# DSPIC33FJ128MC804 register map
Vendor: Microchip
Registers are 16-bit, read-write, reset 0x0 unless marked. A register's access mark holds for its fields unless they carry their own. Addresses are absolute, and some are shared; only a register's first bit layout is shown; [hi:lo] are bit positions; {n}, {i} and the like mark numbered series; 'fields as' and 'values as' point back to an identical list.

## SFR
{0x0+2i} WREG{i} (i=0..14)
0x1E WREG15 reset 0x800
0x20 SPLIM
0x22 ACCAL reset not defined — (power-on value xxxxxxxxxxxxxxxx)
0x24 ACCAH reset not defined — (power-on value xxxxxxxxxxxxxxxx)
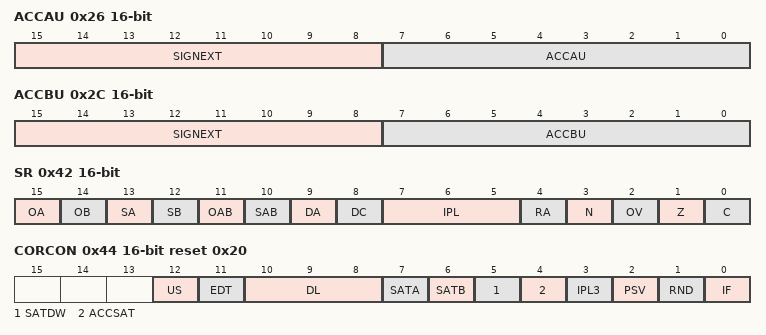
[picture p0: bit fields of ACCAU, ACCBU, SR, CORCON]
0x26 ACCAU reset not defined — (power-on value 00000000xxxxxxxx)
  [15:8] SIGNEXT ro, [7:0] ACCAU
0x28 ACCBL reset not defined — (power-on value xxxxxxxxxxxxxxxx)
0x2A ACCBH reset not defined — (power-on value xxxxxxxxxxxxxxxx)
0x2C ACCBU reset not defined — (power-on value 00000000xxxxxxxx)
  [15:8] SIGNEXT ro, [7:0] ACCBU
0x2E PCL ro
0x30 PCH ro
  [6:0] PCH
0x32 TBLPAG
  [7:0] TBLPAG
0x34 PSVPAG
  [7:0] PSVPAG
0x36 RCOUNT reset not defined — (power-on value --xxxxxxxxxxxxxx)
  [13:0] RCOUNT
0x38 DCOUNT reset not defined — (power-on value --xxxxxxxxxxxxxx)
  [13:0] DCOUNT
0x3A DOSTARTL reset not defined — (power-on value xxxxxxxxxxxxxxx0)
0x3C DOSTARTH reset not defined — (power-on value ----------xxxxxx)
  [5:0] DOSTARTH
0x3E DOENDL reset not defined — (power-on value xxxxxxxxxxxxxxx0)
0x40 DOENDH reset not defined — (power-on value ----------xxxxxx)
  [5:0] DOENDH
0x42 SR
  [15] OA ro
  [14] OB ro
  [13] SA — (can only be cleared)
  [12] SB — (can only be cleared)
  [11] OAB ro
  [10] SAB — (can only be cleared)
  [9] DA ro
  [8] DC
  [7:5] IPL
  [4] RA ro
  [3] N
  [2] OV
  [1] Z
  [0] C
0x44 CORCON reset 0x20
  [12] US
  [11] EDT wo
  [10:8] DL ro
  [7] SATA
  [6] SATB
  [5] SATDW
  [4] ACCSAT
  [3] IPL3 — (can only be cleared)
  [2] PSV
  [1] RND
  [0] IF
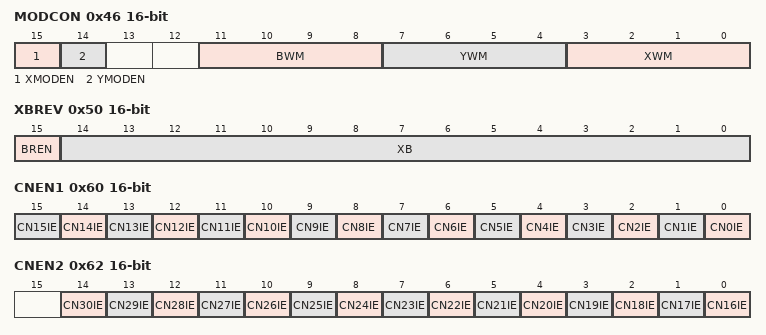
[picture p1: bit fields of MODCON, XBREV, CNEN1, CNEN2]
0x46 MODCON
  [15] XMODEN, [14] YMODEN, [11:8] BWM, [7:4] YWM, [3:0] XWM
0x48 XMODSRT reset not defined — (power-on value xxxxxxxxxxxxxxx0)
  [15:0] XS
0x4A XMODEND reset not defined — (power-on value xxxxxxxxxxxxxxx1)
  [15:0] XE
0x4C YMODSRT reset not defined — (power-on value xxxxxxxxxxxxxxx0)
  [15:0] YS
0x4E YMODEND reset not defined — (power-on value xxxxxxxxxxxxxxx1)
  [15:0] YE
0x50 XBREV reset not defined — (power-on value 0xxxxxxxxxxxxxxx)
  [15] BREN, [14:0] XB
0x52 DISICNT reset not defined — (power-on value --xxxxxxxxxxxxxx)
  [13:0] DISICNT
0x60 CNEN1
  [n] CN{n}IE (n=0..15)
0x62 CNEN2
  [n-16] CN{n}IE (n=16..30)
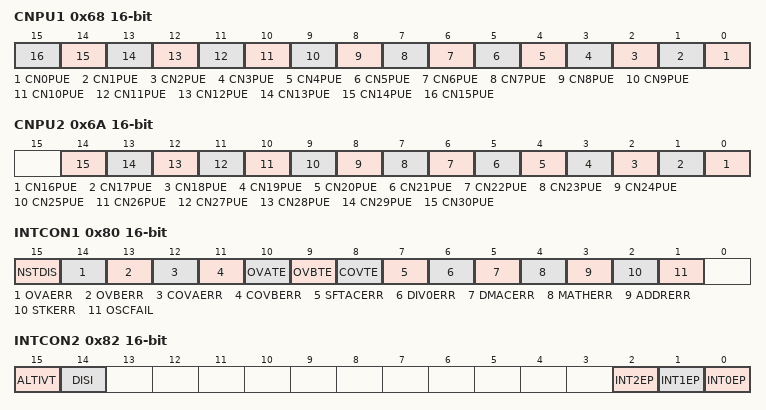
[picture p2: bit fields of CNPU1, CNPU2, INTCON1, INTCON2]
0x68 CNPU1
  [n] CN{n}PUE (n=0..15)
0x6A CNPU2
  [n-16] CN{n}PUE (n=16..30)
0x80 INTCON1
  [15] NSTDIS, [14] OVAERR ro, [13] OVBERR ro, [12] COVAERR ro, [11] COVBERR ro, [10] OVATE, [9] OVBTE, [8] COVTE, [7] SFTACERR ro, [6] DIV0ERR ro, [5] DMACERR, [4] MATHERR, [3] ADDRERR, [2] STKERR, [1] OSCFAIL
0x82 INTCON2
  [15] ALTIVT, [14] DISI ro, [2] INT2EP, [1] INT1EP, [0] INT0EP
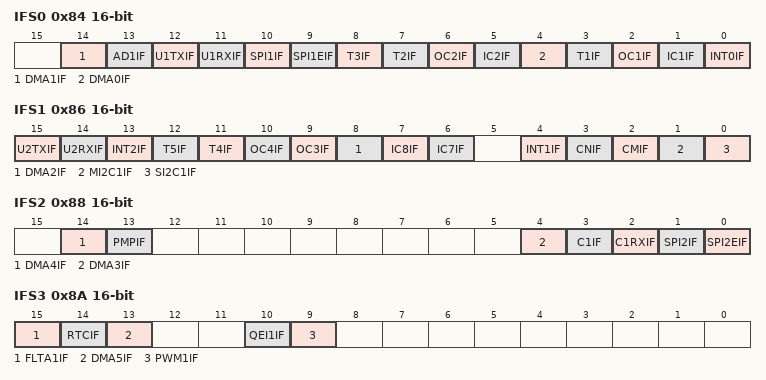
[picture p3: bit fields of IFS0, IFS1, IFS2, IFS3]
0x84 IFS0
  [14] DMA1IF, [13] AD1IF, [12] U1TXIF, [11] U1RXIF, [10] SPI1IF, [9] SPI1EIF, [8] T3IF, [7] T2IF, [6] OC2IF, [5] IC2IF, [4] DMA0IF, [3] T1IF, [2] OC1IF, [1] IC1IF, [0] INT0IF
0x86 IFS1
  [15] U2TXIF, [14] U2RXIF, [13] INT2IF, [12] T5IF, [11] T4IF, [10] OC4IF, [9] OC3IF, [8] DMA2IF, [7] IC8IF, [6] IC7IF, [4] INT1IF, [3] CNIF, [2] CMIF, [1] MI2C1IF, [0] SI2C1IF
0x88 IFS2
  [14] DMA4IF, [13] PMPIF, [4] DMA3IF, [3] C1IF, [2] C1RXIF, [1] SPI2IF, [0] SPI2EIF
0x8A IFS3
  [15] FLTA1IF, [14] RTCIF, [13] DMA5IF, [10] QEI1IF, [9] PWM1IF
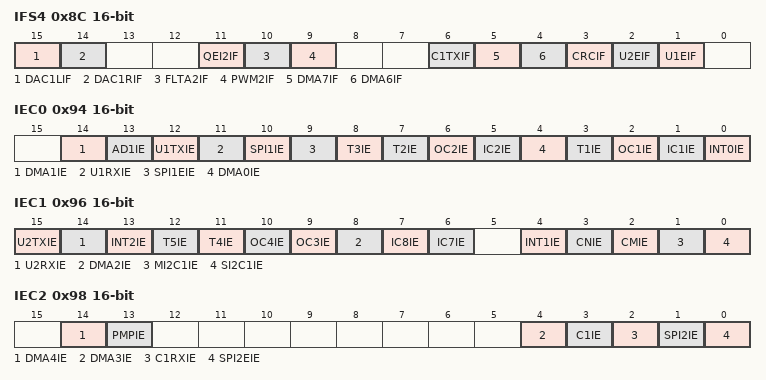
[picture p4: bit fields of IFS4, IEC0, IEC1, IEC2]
0x8C IFS4
  [15] DAC1LIF, [14] DAC1RIF, [11] QEI2IF, [10] FLTA2IF, [9] PWM2IF, [6] C1TXIF, [5] DMA7IF, [4] DMA6IF, [3] CRCIF, [2] U2EIF, [1] U1EIF
0x94 IEC0
  [14] DMA1IE, [13] AD1IE, [12] U1TXIE, [11] U1RXIE, [10] SPI1IE, [9] SPI1EIE, [8] T3IE, [7] T2IE, [6] OC2IE, [5] IC2IE, [4] DMA0IE, [3] T1IE, [2] OC1IE, [1] IC1IE, [0] INT0IE
0x96 IEC1
  [15] U2TXIE, [14] U2RXIE, [13] INT2IE, [12] T5IE, [11] T4IE, [10] OC4IE, [9] OC3IE, [8] DMA2IE, [7] IC8IE, [6] IC7IE, [4] INT1IE, [3] CNIE, [2] CMIE, [1] MI2C1IE, [0] SI2C1IE
0x98 IEC2
  [14] DMA4IE, [13] PMPIE, [4] DMA3IE, [3] C1IE, [2] C1RXIE, [1] SPI2IE, [0] SPI2EIE
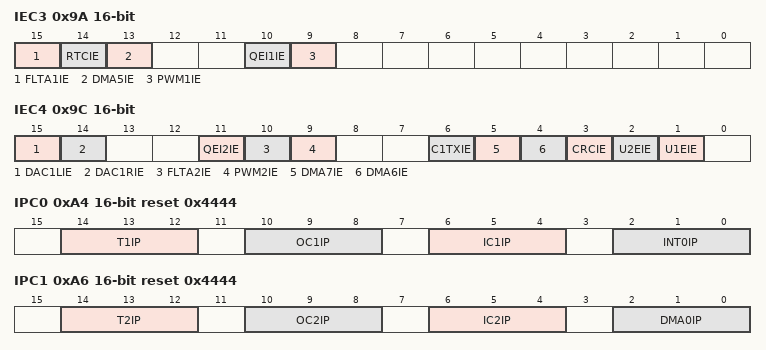
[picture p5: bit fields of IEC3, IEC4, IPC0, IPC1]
0x9A IEC3
  [15] FLTA1IE, [14] RTCIE, [13] DMA5IE, [10] QEI1IE, [9] PWM1IE
0x9C IEC4
  [15] DAC1LIE, [14] DAC1RIE, [11] QEI2IE, [10] FLTA2IE, [9] PWM2IE, [6] C1TXIE, [5] DMA7IE, [4] DMA6IE, [3] CRCIE, [2] U2EIE, [1] U1EIE
0xA4 IPC0 reset 0x4444
  [14:12] T1IP, [10:8] OC1IP, [6:4] IC1IP, [2:0] INT0IP
0xA6 IPC1 reset 0x4444
  [14:12] T2IP, [10:8] OC2IP, [6:4] IC2IP, [2:0] DMA0IP
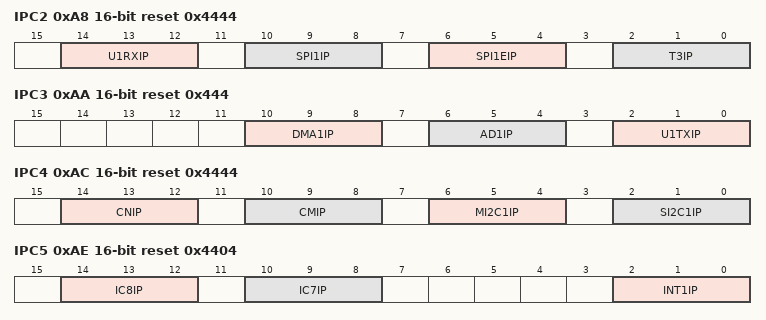
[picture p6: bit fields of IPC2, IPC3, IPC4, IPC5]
0xA8 IPC2 reset 0x4444
  [14:12] U1RXIP, [10:8] SPI1IP, [6:4] SPI1EIP, [2:0] T3IP
0xAA IPC3 reset 0x444
  [10:8] DMA1IP, [6:4] AD1IP, [2:0] U1TXIP
0xAC IPC4 reset 0x4444
  [14:12] CNIP, [10:8] CMIP, [6:4] MI2C1IP, [2:0] SI2C1IP
0xAE IPC5 reset 0x4404
  [14:12] IC8IP, [10:8] IC7IP, [2:0] INT1IP
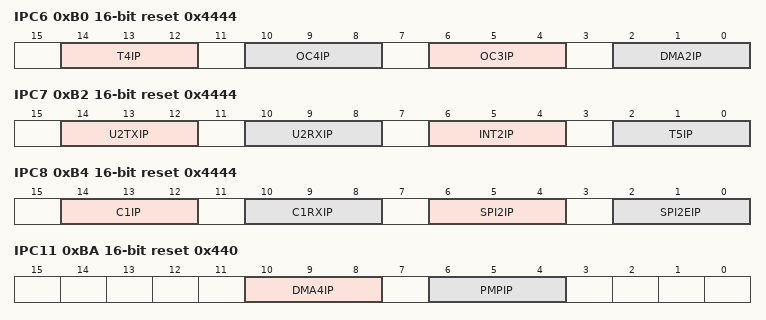
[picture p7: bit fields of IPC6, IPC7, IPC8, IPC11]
0xB0 IPC6 reset 0x4444
  [14:12] T4IP, [10:8] OC4IP, [6:4] OC3IP, [2:0] DMA2IP
0xB2 IPC7 reset 0x4444
  [14:12] U2TXIP, [10:8] U2RXIP, [6:4] INT2IP, [2:0] T5IP
0xB4 IPC8 reset 0x4444
  [14:12] C1IP, [10:8] C1RXIP, [6:4] SPI2IP, [2:0] SPI2EIP
0xB6 IPC9 reset 0x4
  [2:0] DMA3IP
0xBA IPC11 reset 0x440
  [10:8] DMA4IP, [6:4] PMPIP
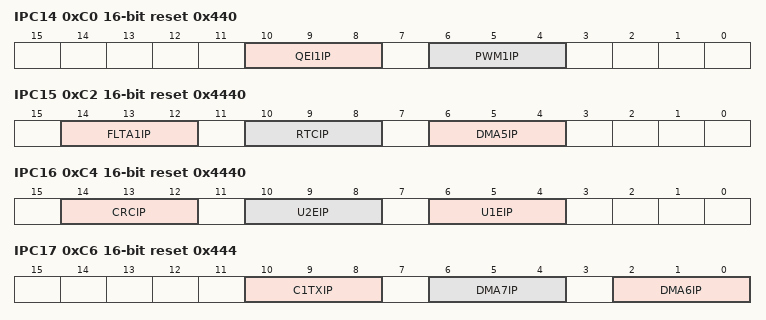
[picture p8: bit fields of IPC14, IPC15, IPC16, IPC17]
0xC0 IPC14 reset 0x440
  [10:8] QEI1IP, [6:4] PWM1IP
0xC2 IPC15 reset 0x4440
  [14:12] FLTA1IP, [10:8] RTCIP, [6:4] DMA5IP
0xC4 IPC16 reset 0x4440
  [14:12] CRCIP, [10:8] U2EIP, [6:4] U1EIP
0xC6 IPC17 reset 0x444
  [10:8] C1TXIP, [6:4] DMA7IP, [2:0] DMA6IP
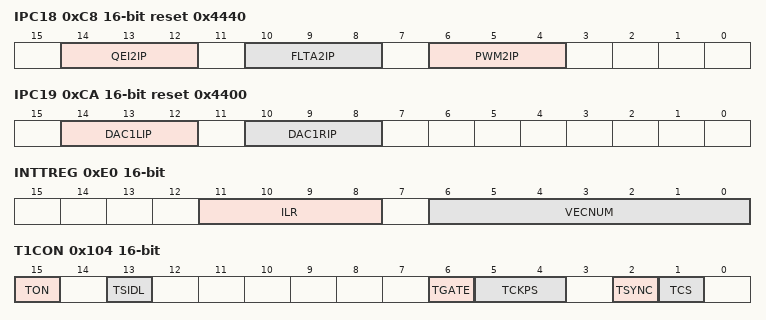
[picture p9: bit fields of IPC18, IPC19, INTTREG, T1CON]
0xC8 IPC18 reset 0x4440
  [14:12] QEI2IP, [10:8] FLTA2IP, [6:4] PWM2IP
0xCA IPC19 reset 0x4400
  [14:12] DAC1LIP, [10:8] DAC1RIP
0xE0 INTTREG ro
  [11:8] ILR, [6:0] VECNUM
0x100 TMR1 reset not defined — (power-on value xxxxxxxxxxxxxxxx)
0x102 PR1 reset 0xFFFF
0x104 T1CON
  [15] TON, [13] TSIDL, [6] TGATE, [5:4] TCKPS, [2] TSYNC, [1] TCS
0x106 TMR2 reset not defined — (power-on value xxxxxxxxxxxxxxxx)
0x108 TMR3HLD reset not defined — (power-on value xxxxxxxxxxxxxxxx)
0x10A TMR3 reset not defined — (power-on value xxxxxxxxxxxxxxxx)
0x10C PR2 reset 0xFFFF
0x10E PR3 reset 0xFFFF
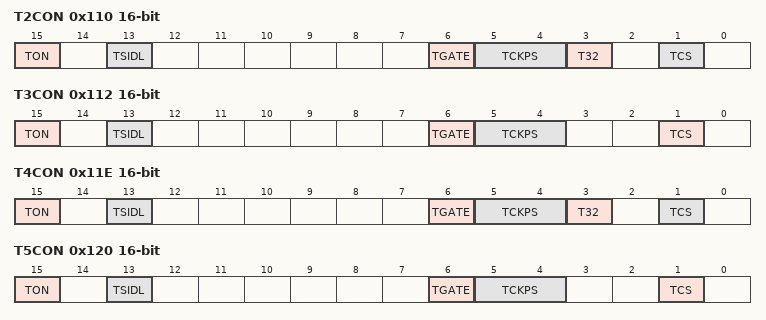
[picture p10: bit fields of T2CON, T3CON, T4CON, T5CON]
0x110 T2CON
  [15] TON, [13] TSIDL, [6] TGATE, [5:4] TCKPS, [3] T32, [1] TCS
0x112 T3CON
  [15] TON, [13] TSIDL, [6] TGATE, [5:4] TCKPS, [1] TCS
0x114 TMR4 reset not defined — (power-on value xxxxxxxxxxxxxxxx)
0x116 TMR5HLD reset not defined — (power-on value xxxxxxxxxxxxxxxx)
0x118 TMR5 reset not defined — (power-on value xxxxxxxxxxxxxxxx)
0x11A PR4 reset 0xFFFF
0x11C PR5 reset 0xFFFF
0x11E T4CON
  [15] TON, [13] TSIDL, [6] TGATE, [5:4] TCKPS, [3] T32, [1] TCS
0x120 T5CON
  [15] TON, [13] TSIDL, [6] TGATE, [5:4] TCKPS, [1] TCS
0x140 IC1BUF ro reset not defined — (power-on value xxxxxxxxxxxxxxxx)
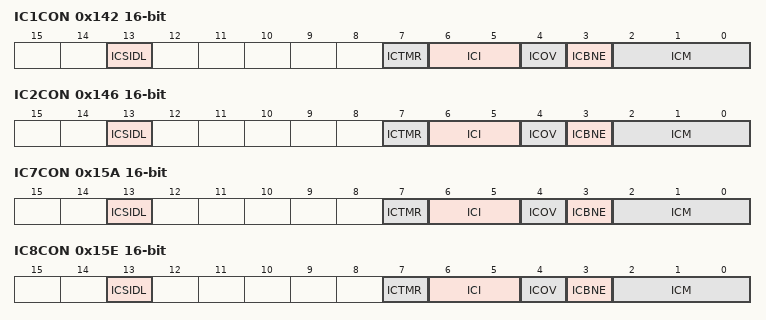
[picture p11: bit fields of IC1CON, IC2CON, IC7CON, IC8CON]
0x142 IC1CON
  [13] ICSIDL, [7] ICTMR, [6:5] ICI, [4] ICOV ro, [3] ICBNE ro, [2:0] ICM
0x144 IC2BUF ro reset not defined — (power-on value xxxxxxxxxxxxxxxx)
0x146 IC2CON
  fields as IC1CON
0x158 IC7BUF ro reset not defined — (power-on value xxxxxxxxxxxxxxxx)
0x15A IC7CON
  fields as IC1CON
0x15C IC8BUF ro reset not defined — (power-on value xxxxxxxxxxxxxxxx)
0x15E IC8CON
  fields as IC1CON
{0x17A+6i} OC{i}RS reset not defined (i=1..4) — (power-on value xxxxxxxxxxxxxxxx)
{0x17C+6i} OC{i}R reset not defined (i=1..4) — (power-on value xxxxxxxxxxxxxxxx)
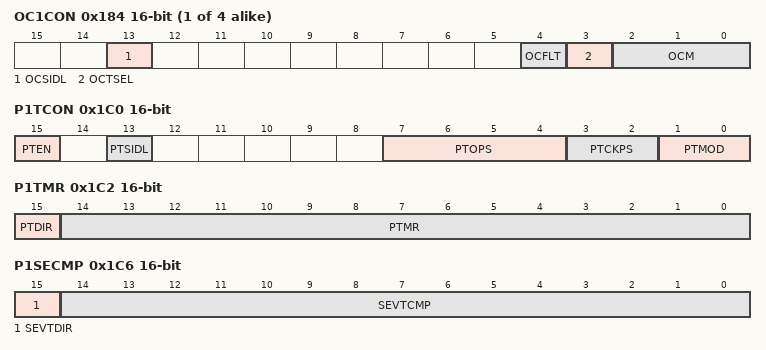
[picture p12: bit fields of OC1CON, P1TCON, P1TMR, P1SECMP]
{0x17E+6i} OC{i}CON (i=1..4)
  [13] OCSIDL, [4] OCFLT ro, [3] OCTSEL, [2:0] OCM
0x1C0 P1TCON
  [15] PTEN, [13] PTSIDL, [7:4] PTOPS, [3:2] PTCKPS, [1:0] PTMOD
0x1C2 P1TMR
  [15] PTDIR ro, [14:0] PTMR
0x1C4 P1TPER
  [14:0] PTPER
0x1C6 P1SECMP
  [15] SEVTDIR, [14:0] SEVTCMP
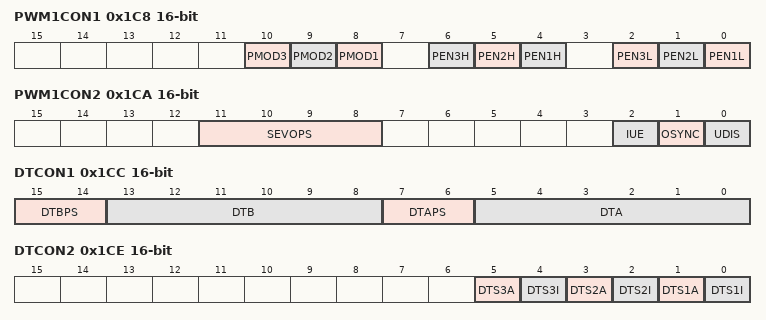
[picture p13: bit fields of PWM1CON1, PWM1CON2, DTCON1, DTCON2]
0x1C8 PWM1CON1
  [10] PMOD3, [9] PMOD2, [8] PMOD1, [6] PEN3H, [5] PEN2H, [4] PEN1H, [2] PEN3L, [1] PEN2L, [0] PEN1L
0x1CA PWM1CON2
  [11:8] SEVOPS, [2] IUE, [1] OSYNC, [0] UDIS
0x1CC DTCON1
  [15:14] DTBPS, [13:8] DTB, [7:6] DTAPS, [5:0] DTA
0x1CE DTCON2
  [5] DTS3A, [4] DTS3I, [3] DTS2A, [2] DTS2I, [1] DTS1A, [0] DTS1I
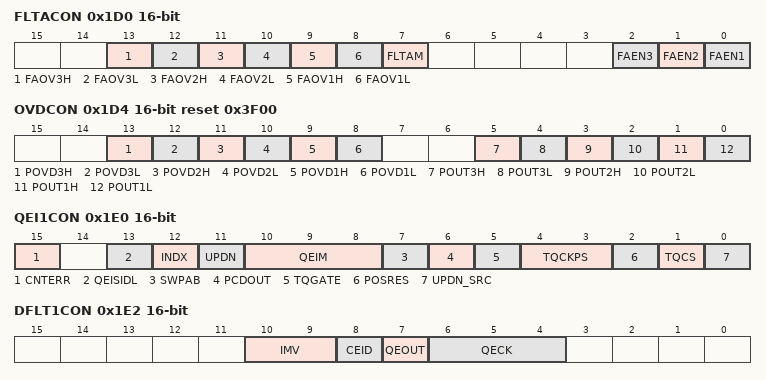
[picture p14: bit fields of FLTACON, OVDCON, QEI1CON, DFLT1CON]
0x1D0 FLTACON
  [13] FAOV3H, [12] FAOV3L, [11] FAOV2H, [10] FAOV2L, [9] FAOV1H, [8] FAOV1L, [7] FLTAM, [2] FAEN3, [1] FAEN2, [0] FAEN1
0x1D4 OVDCON reset 0x3F00
  [13] POVD3H, [12] POVD3L, [11] POVD2H, [10] POVD2L, [9] POVD1H, [8] POVD1L, [5] POUT3H, [4] POUT3L, [3] POUT2H, [2] POUT2L, [1] POUT1H, [0] POUT1L
{0x1D4+2i} P1DC{i} (i=1..3)
  [15:0] PDC{i}
0x1E0 QEI1CON
  [15] CNTERR, [13] QEISIDL, [12] INDX, [11] UPDN, [10:8] QEIM, [7] SWPAB, [6] PCDOUT, [5] TQGATE, [4:3] TQCKPS, [2] POSRES, [1] TQCS, [0] UPDN_SRC
0x1E2 DFLT1CON
  [10:9] IMV, [8] CEID, [7] QEOUT, [6:4] QECK
0x1E4 POS1CNT
0x1E6 MAX1CNT
0x1F0 QEI2CON
  fields as QEI1CON
0x1F2 DFLT2CON
  [10:9] IMV, [8] CEID, [7] QEOUT, [6:4] QECK
0x1F4 POS2CNT
0x1F6 MAX2CNT
0x200 I2C1RCV ro
  [7:0] I2C1RCV
0x202 I2C1TRN wo reset 0xFF
  [7:0] I2C1TRN
0x204 I2C1BRG
  [8:0] I2C1BRG
0x206 I2C1CON reset 0x1000
  [15] I2CEN, [13] I2CSIDL, [12] SCLREL, [11] IPMIEN, [10] A10M, [9] DISSLW, [8] SMEN, [7] GCEN, [6] STREN, [5] ACKDT, [4] ACKEN, [3] RCEN, [2] PEN, [1] RSEN, [0] SEN
0x208 I2C1STAT
  [15] ACKSTAT ro
  [14] TRSTAT ro
  [10] BCL ro
  [9] GCSTAT ro
  [8] ADD10 ro
  [7] IWCOL — (can only be cleared)
  [6] I2COV — (can only be cleared)
  [5] D_A ro
  [4] P — (can only be cleared)
  [3] S — (can only be cleared)
  [2] R_W ro
  [1] RBF ro
  [0] TBF ro
0x20A I2C1ADD
  [9:0] I2C1ADD
0x20C I2C1MSK
  [9:0] AMSK
0x220 U1MODE
  [15] UARTEN, [13] USIDL, [12] IREN, [11] RTSMD, [9:8] UEN, [7] WAKE, [6] LPBACK, [5] ABAUD, [4] URXINV, [3] BRGH, [2:1] PDSEL, [0] STSEL
0x222 U1STA reset 0x110
  [15] UTXISEL1
  [14] UTXINV
  [13] UTXISEL0
  [11] UTXBRK
  [10] UTXEN
  [9] UTXBF ro
  [8] TRMT ro
  [7:6] URXISEL
  [5] ADDEN
  [4] RIDLE ro
  [3] PERR ro
  [2] FERR ro
  [1] OERR — (can only be cleared)
  [0] URXDA ro
0x224 U1TXREG wo
  [n] UTXREG{n} (n=0..8)
0x226 U1RXREG ro
  [n] URXREG{n} (n=0..8)
0x228 U1BRG
  [15:0] BRG
0x230 U2MODE
  fields as U1MODE
0x232 U2STA reset 0x110
  fields as U1STA
0x234 U2TXREG wo
  [n] UTXREG{n} (n=0..8)
0x236 U2RXREG ro
  [n] URXREG{n} (n=0..8)
0x238 U2BRG
  [15:0] BRG
0x240 SPI1STAT
  [15] SPIEN
  [13] SPISIDL
  [6] SPIROV — (can only be cleared)
  [1] SPITBF
  [0] SPIRBF
0x242 SPI1CON1
  [12] DISSCK, [11] DISSDO, [10] MODE16, [9] SMP, [8] CKE, [7] SSEN, [6] CKP, [5] MSTEN, [4:2] SPRE, [1:0] PPRE
0x244 SPI1CON2
  [15] FRMEN, [14] SPIFSD, [13] FRMPOL, [1] FRMDLY
0x248 SPI1BUF
0x260 SPI2STAT
  fields as SPI1STAT
0x262 SPI2CON1
  fields as SPI1CON1
0x264 SPI2CON2
  [15] FRMEN, [14] SPIFSD, [13] FRMPOL, [1] FRMDLY
0x268 SPI2BUF
0x2C0 TRISA reset 0x79F
  [n] TRISA{n} (n=7..10), [n] TRISA{n} (n=0..4)
0x2C2 PORTA reset not defined — (power-on value -----xxxx--xxxxx)
  [n] RA{n} (n=7..10), [n] RA{n} (n=0..4)
0x2C4 LATA
  [n] LATA{n} (n=7..10), [n] LATA{n} (n=0..4)
0x2C6 ODCA
  [n] ODCA{n} (n=7..10), [n] ODCA{n} (n=0..4)
0x2C8 TRISB reset 0xFFFF
  [n] TRISB{n} (n=0..15)
0x2CA PORTB reset not defined — (power-on value xxxxxxxxxxxxxxxx)
  [n] RB{n} (n=0..15)
0x2CC LATB
  [n] LATB{n} (n=0..15)
0x2CE ODCB
  [n] ODCB{n} (n=0..15)
0x2D0 TRISC reset 0x3FF
  [n] TRISC{n} (n=0..9)
0x2D2 PORTC reset not defined — (power-on value ------xxxxxxxxxx)
  [n] RC{n} (n=0..9)
0x2D4 LATC
  [n] LATC{n} (n=0..9)
0x2D6 ODCC
  [n] ODCC{n} (n=0..9)
0x2FC PADCFG1
  [1] RTSECSEL, [0] PMPTTL
0x300 ADC1BUF0 ro reset not defined — (power-on value xxxxxxxxxxxxxxxx)
  [15:0] ADCBUF0
0x320 AD1CON1
  [15] ADON
  [13] ADSIDL
  [12] ADDMABM
  [10] AD12B
  [9:8] FORM
  [7:5] SSRC
  [3] SIMSAM
  [2] ASAM
  [1] SAMP
  [0] DONE — (can only be cleared)
0x322 AD1CON2
  [15:13] VCFG, [10] CSCNA, [9:8] CHPS, [7] BUFS ro, [5:2] SMPI, [1] BUFM, [0] ALTS
0x324 AD1CON3
  [15] ADRC, [12:8] SAMC, [7:0] ADCS
0x326 AD1CHS123
  [10:9] CH123NB, [8] CH123SB, [2:1] CH123NA, [0] CH123SA
0x328 AD1CHS0
  [15] CH0NB, [12:8] CH0SB, [7] CH0NA, [4:0] CH0SA
0x32C AD1PCFGL
  [n] PCFG{n} (n=0..8)
0x330 AD1CSSL
  [n] CSS{n} (n=0..8)
0x332 AD1CON4
  [2:0] DMABL
{0x380+0xC*i} DMA{i}CON (i=0..7)
  [15] CHEN, [14] SIZE, [13] DIR, [12] HALF, [11] NULLW, [5:4] AMODE, [1:0] MODE
{0x382+0xC*i} DMA{i}REQ (i=0..7)
  [15] FORCE — (can only be set)
  [6:0] IRQSEL
{0x384+0xC*i} DMA{i}STA (i=0..7)
  [15:0] STA
{0x386+0xC*i} DMA{i}STB (i=0..7)
  [15:0] STB
{0x388+0xC*i} DMA{i}PAD (i=0..7)
  [15:0] PAD
{0x38A+0xC*i} DMA{i}CNT (i=0..7)
  [15:0] CNT
0x3E0 DMACS0 ro
  [15:8] PWCOL, [7:0] XWCOL
0x3E2 DMACS1 ro reset 0xF00
  [11:8] LSTCH, [n] PPST{n} (n=0..7)
0x3E4 DSADR ro
0x3F0 DAC1CON
  [15] DACEN, [13] DACSIDL, [12] AMPON, [8] FORM, [6:0] DACFDIV
0x3F2 DAC1STAT
  [15] LOEN, [13] LMVOEN, [10] LITYPE, [9] LFULL ro, [8] LEMPTY ro, [7] ROEN, [5] RMVOEN, [2] RITYPE, [0] REMPTY ro
0x3F4 DAC1DFLT
  [15:0] DACDFLT
0x3F6 DAC1RDAT
  [15:0] DACRDAT
0x3F8 DAC1LDAT
  [15:0] DACLDAT
0x400 C1CTRL1 reset 0x480
  [13] CSIDL, [12] ABAT, [11] CANCKS, [10:8] REQOP, [7:5] OPMODE ro, [3] CANCAP, [0] WIN
0x402 C1CTRL2 ro
  [4:0] DNCNT
0x404 C1VEC ro reset 0x40
  [12:8] FILHIT, [6:0] ICODE
0x406 C1FCTRL
  [15:13] DMABS, [4:0] FSA
0x408 C1FIFO ro
  [13:8] FBP, [5:0] FNRB
0x40A C1INTF
  [13] TXBO ro
  [12] TXBP ro
  [11] RXBP ro
  [10] TXWAR ro
  [9] RXWAR ro
  [8] EWARN ro
  [7] IVRIF — (can only be cleared)
  [6] WAKIF — (can only be cleared)
  [5] ERRIF — (can only be cleared)
  [3] FIFOIF — (can only be cleared)
  [2] RBOVIF — (can only be cleared)
  [1] RBIF — (can only be cleared)
  [0] TBIF — (can only be cleared)
0x40C C1INTE
  [7] IVRIE, [6] WAKIE, [5] ERRIE, [3] FIFOIE, [2] RBOVIE, [1] RBIE, [0] TBIE
0x40E C1EC
  [15:8] TERRCNT, [7:0] RERRCNT
0x410 C1CFG1
  [7:6] SJW, [5:0] BRP
0x412 C1CFG2
  [14] WAKFIL, [10:8] SEG2PH, [7] SEG2PHTS, [6] SAM, [5:3] SEG1PH, [2:0] PRSEG
0x414 C1FEN1
  [15:0] FLTEN
0x418 C1FMSKSEL1
  [2n+1:2n] F{n}MSK (n=0..7)
0x41A C1FMSKSEL2
  [2n-15:2n-16] F{n}MSK (n=8..15)
0x420 C1RXFUL1
  [n] RXFUL{n} (n=0..15) — (can only be cleared)
0x420 C1BUFPNT1
  [4n+3:4n] F{n}BP (n=0..3)
0x422 C1RXFUL2
  [n-16] RXFUL{n} (n=16..31) — (can only be cleared)
0x422 C1BUFPNT2
  [4n-13:4n-16] F{n}BP (n=4..7)
0x424 C1BUFPNT3
  [4n-29:4n-32] F{n}BP (n=8..11)
0x426 C1BUFPNT4
  [4n-45:4n-48] F{n}BP (n=12..15)
0x428 C1RXOVF1
  [n] RXOVF{n} (n=0..15) — (can only be cleared)
0x42A C1RXOVF2
  [n-16] RXOVF{n} (n=16..31) — (can only be cleared)
0x430 C1TR01CON
  [15] TXEN1, [14] TXABT1 ro, [13] TXLARB1 ro, [12] TXERR1 ro, [11] TXREQ1, [10] RTREN1, [9:8] TX1PRI, [7] TXEN0, [6] TXABT0 ro, [5] TXLARB0 ro, [4] TXERR0 ro, [3] TXREQ0, [2] RTREN0, [1:0] TX0PRI
{0x430+4i} C1RXM{i}SID (i=0..2)
  [n+5] SID{n} (n=0..10), [3] MIDE, [1] EID17, [0] EID16
0x432 C1TR23CON
  [15] TXEN3, [14] TXABT3 ro, [13] TXLARB3 ro, [12] TXERR3 ro, [11] TXREQ3, [10] RTREN3, [9:8] TX3PRI, [7] TXEN2, [6] TXABT2 ro, [5] TXLARB2 ro, [4] TXERR2 ro, [3] TXREQ2, [2] RTREN2, [1:0] TX2PRI
{0x432+4i} C1RXM{i}EID (i=0..2)
  [n] EID{n} (n=0..15)
0x434 C1TR45CON
  [15] TXEN5, [14] TXABT5 ro, [13] TXLARB5 ro, [12] TXERR5 ro, [11] TXREQ5, [10] RTREN5, [9:8] TX5PRI, [7] TXEN4, [6] TXABT4 ro, [5] TXLARB4 ro, [4] TXERR4 ro, [3] TXREQ4, [2] RTREN4, [1:0] TX4PRI
0x436 C1TR67CON
  [15] TXEN7, [14] TXABT7 ro, [13] TXLARB7 ro, [12] TXERR7 ro, [11] TXREQ7, [10] RTREN7, [9:8] TX7PRI, [7] TXEN6, [6] TXABT6 ro, [5] TXLARB6 ro, [4] TXERR6 ro, [3] TXREQ6, [2] RTREN6, [1:0] TX6PRI
0x440 C1RXD reset not defined — (power-on value uuuuuuuuuuuuuuuu)
{0x440+4i} C1RXF{i}SID (i=0..15)
  [15:5] SID, [3] EXIDE, [1:0] EID
0x442 C1TXD
  [15:1] C1TXD
{0x442+4i} C1RXF{i}EID (i=0..15)
  [15:0] EID
0x5C0 P2TCON
  [15] PTEN, [13] PTSIDL, [7:4] PTOPS, [3:2] PTCKPS, [1:0] PTMOD
0x5C2 P2TMR
  [15] PTDIR ro, [14:0] PTMR
0x5C4 P2TPER
  [14:0] PTPER
0x5C6 P2SECMP
  [15] SEVTDIR, [14:0] SEVTCMP
0x5C8 PWM2CON1
  [8] PMOD1, [4] PEN1H, [0] PEN1L
0x5CA PWM2CON2
  [11:8] SEVOPS, [2] IUE, [1] OSYNC, [0] UDIS
0x5CC P2DTCON1
  [15:14] DTBPS, [13:8] DTB, [7:6] DTAPS, [5:0] DTA
0x5CE P2DTCON2
  [1] DTS1A, [0] DTS1I
0x5D0 P2FLTACON
  [9] FAOV1H, [8] FAOV1L, [7] FLTAM, [0] FAEN1
0x5D4 P2OVDCON reset 0x300
  [9] POVD1H, [8] POVD1L, [1] POUT1H, [0] POUT1L
0x5D6 P2DC1
0x600 PMCON
  [15] PMPEN, [13] PSIDL, [12:11] ADRMUX, [10] PTBEEN, [9] PTWREN, [8] PTRDEN, [7:6] CSF, [5] ALP, [3] CS1P, [2] BEP, [1] WRSP, [0] RDSP
0x602 PMMODE
  [15] BUSY, [14:13] IRQM, [12:11] INCM, [10] MODE16, [9:8] MODE, [7:6] WAITB, [5:2] WAITM, [1:0] WAITE
0x604 PMADDR
  [15] ADDR15, [14] CS1, [13:0] ADDR
0x604 PMDOUT1
  [15:0] DATA
0x606 PMDOUT2
  [15:0] DATA
0x608 PMDIN1
  [15:0] DATA
0x60A PMDIN2
  [15:0] PTEN
0x60C PMAEN
  [14] PTEN14, [10:0] PTEN
0x60E PMSTAT
  [15] IBF, [14] IBOV, [n+8] IB{n}F (n=0..3), [7] OBE, [6] OBUF, [n] OB{n}E (n=0..3)
0x620 ALRMVAL
0x622 ALCFGRPT
  [15] ALRMEN, [14] CHIME, [13:10] AMASK, [9:8] ALRMPTR, [7:0] ARPT
0x624 RTCVAL
0x626 RCFGCAL
  [15] RTCEN, [13] RTCWREN, [12] RTCSYNC, [11] HALFSEC, [10] RTCOE, [9:8] RTCPTR, [7:0] CAL
0x630 CMCON
  [15] CMIDL, [13] C2EVT, [12] C1EVT, [11] C2EN, [10] C1EN, [9] C2OUTEN, [8] C1OUTEN, [7] C2OUT ro, [6] C1OUT ro, [5] C2INV, [4] C1INV, [3] C2NEG, [2] C2POS, [1] C1NEG, [0] C1POS
0x632 CVRCON
  [7] CVREN, [6] CVROE, [5] CVRR, [4] CVRSS, [3:0] CVR
0x640 CRCCON reset 0x40
  [13] CSIDL, [12:8] VWORD ro, [7] CRCFUL ro, [6] CRCMPT ro, [4] CRCGO, [3:0] PLEN
0x642 CRCXOR
0x644 CRCDAT
0x646 CRCWDAT
0x680 RPINR0 reset 0x1F00
  [12:8] INT1R
0x682 RPINR1 reset 0x1F
  [4:0] INT2R
0x686 RPINR3 reset 0x1F1F
  [12:8] T3CKR, [4:0] T2CKR
0x688 RPINR4 reset 0x1F1F
  [12:8] T5CKR, [4:0] T4CKR
0x68E RPINR7 reset 0x1F1F
  [12:8] IC2R, [4:0] IC1R
0x694 RPINR10 reset 0x1F1F
  [12:8] IC8R, [4:0] IC7R
0x696 RPINR11 reset 0x1F
  [4:0] OCFAR
0x698 RPINR12 reset 0x1F
  [4:0] FLTA1R
0x69A RPINR13 reset 0x1F
  [4:0] FLTA2R
0x69C RPINR14 reset 0x1F1F
  [12:8] QEB1R, [4:0] QEA1R
0x69E RPINR15 reset 0x1F
  [4:0] INDX1R
0x6A0 RPINR16 reset 0x1F1F
  [12:8] QEB2R, [4:0] QEA2R
0x6A2 RPINR17 reset 0x1F
  [4:0] INDX2R
0x6A4 RPINR18 reset 0x1F1F
  [12:8] U1CTSR, [4:0] U1RXR
0x6A6 RPINR19 reset 0x1F1F
  [12:8] U2CTSR, [4:0] U2RXR
0x6A8 RPINR20 reset 0x1F1F
  [12:8] SCK1R, [4:0] SDI1R
0x6AA RPINR21 reset 0x1F
  [4:0] SS1R
0x6AC RPINR22 reset 0x1F1F
  [12:8] SCK2R, [4:0] SDI2R
0x6AE RPINR23 reset 0x1F
  [4:0] SS2R
0x6B4 RPINR26 reset 0x1F
  [4:0] C1RXR
{0x6C0+2i} RPOR{i} (i=0..12)
  [12:8] RP{2i+1}R, [4:0] RP{2i}R
0x740 RCON reset 0x3
  [15] TRAPR, [14] IOPUWR, [9] CM, [8] VREGS, [7] EXTR, [6] SWR, [5] SWDTEN, [4] WDTO, [3] SLEEP, [2] IDLE, [1] BOR, [0] POR
0x742 OSCCON reset not defined — (power-on value -000-yyy000-0-00)
  [14:12] COSC ro
  [10:8] NOSC
  [7] CLKLOCK
  [6] IOLOCK
  [5] LOCK ro
  [3] CF — (can only be cleared)
  [1] LPOSCEN
  [0] OSWEN
0x744 CLKDIV reset 0x3040
  [15] ROI, [14:12] DOZE, [11] DOZEN, [10:8] FRCDIV, [7:6] PLLPOST, [4:0] PLLPRE
0x746 PLLFBD
  [8:0] PLLDIV
0x748 OSCTUN
  [5:0] TUN
0x74A ACLKCON reset not defined — (power-on value --xxxxxxx-------)
  [13] SELACLK, [12:11] AOSCMD, [10:8] APSTSCLR, [7] ASRCSEL
0x750 BSRAM
  [2] IW_BSR, [1] IR_BSR, [0] RL_BSR
0x752 SSRAM
  [2] IW_SSR, [1] IR_SSR, [0] RL_SSR
0x760 NVMCON
  [15] WR — (can only be set)
  [14] WREN
  [13] WRERR
  [6] ERASE
  [3:0] NVMOP
0x766 NVMKEY wo
  [7:0] NVMKEY
0x770 PMD1 reset not defined — (power-on value 00000xx-00000-00)
  [n+10] T{n}MD (n=1..5), [10] QEI1MD, [9] PWM1MD, [7] I2C1MD, [6] U2MD, [5] U1MD, [4] SPI2MD, [3] SPI1MD, [1] C1MD, [0] AD1MD
0x772 PMD2
  [15] IC8MD, [14] IC7MD, [9] IC2MD, [8] IC1MD, [n-1] OC{n}MD (n=1..4)
0x774 PMD3 reset not defined — (power-on value -----00000xx----)
  [10] CMPMD, [9] RTCCMD, [8] PMPMD, [7] CRCMD, [6] DAC1MD, [5] QEI2MD, [4] PWM2MD
